VERSION ""

NS_ :

BS_:

BU_: VCU IPC
VAL_TABLE_ Flag 1 "Active" 0 "Not Active" ;

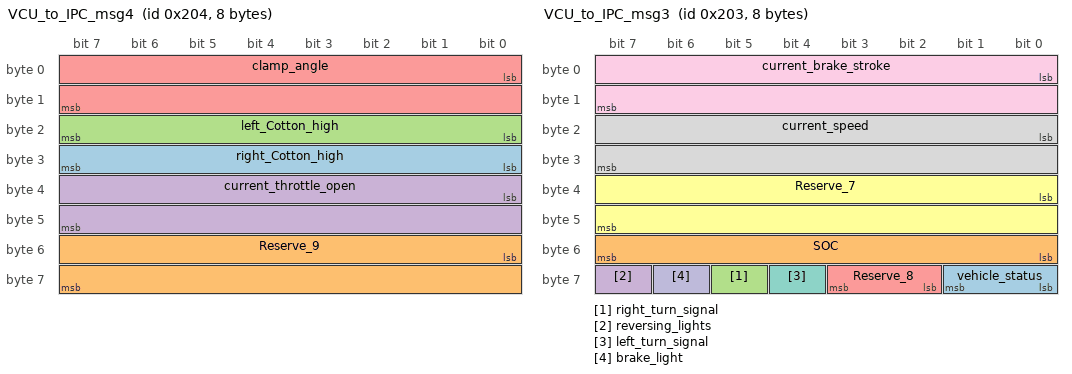
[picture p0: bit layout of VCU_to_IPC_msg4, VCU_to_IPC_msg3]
BO_ 516 VCU_to_IPC_msg4: 8 Vector__XXX
 SG_ right_Cotton_high : 24|8@1+ (1,0) [0|255] "cm"  IPC
 SG_ Reserve_9 : 48|16@1+ (1,0) [0|65535] ""  IPC
 SG_ left_Cotton_high : 16|8@1+ (1,0) [0|255] "cm"  IPC
 SG_ current_throttle_open : 32|16@1- (0.1,0) [-3276.8|3276.7] "%"  IPC
 SG_ clamp_angle : 0|16@1- (0.1,0) [-3276.8|3276.7] ""  IPC

BO_ 515 VCU_to_IPC_msg3: 8 VCU
 SG_ vehicle_status : 56|2@1+ (1,0) [0|3] ""  IPC
 SG_ SOC : 48|8@1+ (1,0) [0|255] ""  IPC
 SG_ right_turn_signal : 61|1@1+ (1,0) [0|1] ""  IPC
 SG_ reversing_lights : 63|1@1+ (1,0) [0|1] ""  IPC
 SG_ Reserve_8 : 58|2@1+ (1,0) [0|3] ""  IPC
 SG_ Reserve_7 : 32|16@1+ (1,0) [0|65535] ""  IPC
 SG_ left_turn_signal : 60|1@1+ (1,0) [0|1] ""  IPC
 SG_ current_speed : 16|16@1+ (1,0) [0|65535] ""  IPC
 SG_ current_brake_stroke : 0|16@1+ (1,0) [0|65535] ""  IPC
 SG_ brake_light : 62|1@1+ (1,0) [0|1] ""  IPC

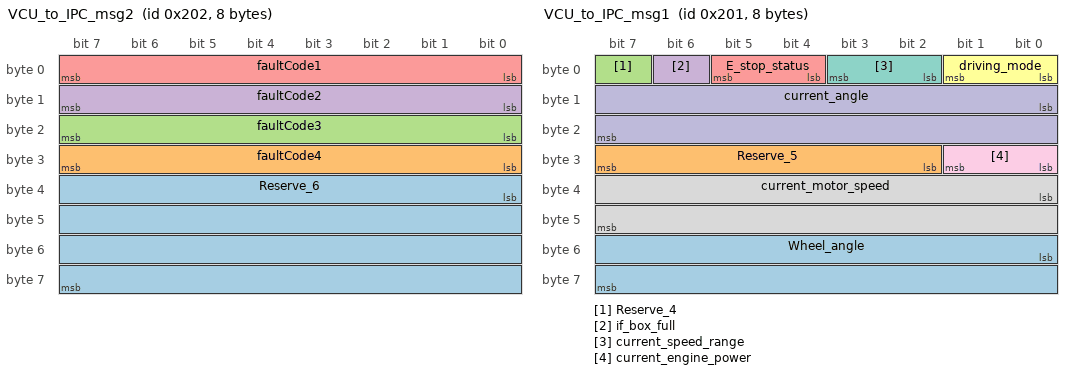
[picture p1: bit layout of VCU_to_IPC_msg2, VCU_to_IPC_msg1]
BO_ 514 VCU_to_IPC_msg2: 8 VCU
 SG_ Reserve_6 : 32|32@1+ (1,0) [0|4294967295] ""  IPC
 SG_ faultCode4 : 24|8@1+ (1,0) [0|255] ""  IPC
 SG_ faultCode3 : 16|8@1+ (1,0) [0|255] ""  IPC
 SG_ faultCode2 : 8|8@1+ (1,0) [0|255] ""  IPC
 SG_ faultCode1 : 0|8@1+ (1,0) [0|255] ""  IPC

BO_ 513 VCU_to_IPC_msg1: 8 VCU
 SG_ Wheel_angle : 48|16@1- (0.01,0) [-327.68|327.67] ""  IPC
 SG_ Reserve_5 : 26|6@1+ (1,0) [0|63] ""  IPC
 SG_ Reserve_4 : 7|1@1+ (1,0) [0|1] ""  IPC
 SG_ if_box_full : 6|1@1+ (1,0) [0|1] ""  IPC
 SG_ E_stop_status : 4|2@1+ (1,0) [0|3] ""  IPC
 SG_ driving_mode : 0|2@1+ (1,0) [0|3] ""  IPC
 SG_ current_speed_range : 2|2@1+ (1,0) [0|3] ""  IPC
 SG_ current_motor_speed : 32|16@1+ (1,-20000) [-20000|45535] "r/min"  IPC
 SG_ current_engine_power : 24|2@1+ (1,0) [0|3] ""  IPC
 SG_ current_angle : 8|16@1- (1,0) [-32768|32767] ""  IPC

BO_ 528 IPC_to_VCU_msg1: 8 IPC
 SG_ Target_turn_light : 57|2@1+ (1,0) [0|3] ""  VCU
 SG_ Target_steering_angle : 32|16@1- (1,0) [-32768|32767] "deg"  VCU
 SG_ Target_Fan_gear : 29|2@1+ (1,0) [0|3] ""  VCU
 SG_ Reserve_3 : 61|3@1+ (1,0) [0|7] ""  VCU
 SG_ Reserve_2 : 56|1@1+ (1,0) [0|1] ""  VCU
 SG_ Reserve_1 : 31|1@1+ (1,0) [0|1] ""  VCU
 SG_ Door_control : 59|2@1+ (1,0) [0|3] ""  VCU
 SG_ brake_pressure_request : 49|7@1+ (1,0) [0|127] ""  VCU
 SG_ brake_enable : 48|1@1+ (1,0) [0|1] ""  VCU
 SG_ throttle_opening : 8|16@1- (0.1,0) [-3276.8|3276.7] "%"  VCU
 SG_ speed_range : 6|2@1+ (1,0) [0|3] ""  VCU
 SG_ Head_control : 24|3@1+ (1,0) [0|7] ""  VCU
 SG_ Engine_power : 27|2@1+ (1,0) [0|3] ""  VCU
 SG_ cotton_unloading : 4|1@1+ (1,0) [0|1] ""  VCU
 SG_ cotton_picker_enable : 3|1@1+ (1,0) [0|1] ""  VCU
 SG_ cotton_box_control : 0|3@1+ (1,0) [0|7] ""  VCU
 SG_ auto_enable : 5|1@1+ (1,0) [0|1] ""  VCU

VAL_ 515 right_turn_signal 1 "Active" 0 "Not Active" ;
VAL_ 515 reversing_lights 1 "Active" 0 "Not Active" ;
VAL_ 515 left_turn_signal 1 "Active" 0 "Not Active" ;
VAL_ 515 brake_light 1 "Active" 0 "Not Active" ;
VAL_ 513 if_box_full 1 "Active" 0 "Not Active" ;
VAL_ 528 cotton_unloading 1 "Active" 0 "Not Active" ;
VAL_ 528 cotton_picker_enable 1 "Active" 0 "Not Active" ;
VAL_ 528 auto_enable 1 "Active" 0 "Not Active" ;
